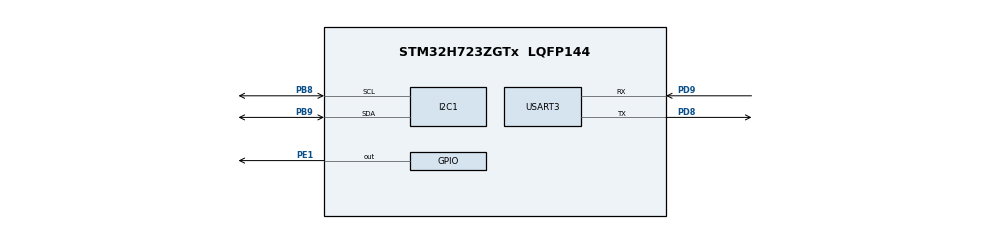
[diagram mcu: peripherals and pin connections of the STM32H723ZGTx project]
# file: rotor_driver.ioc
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CORTEX_M7.AccessPermission-Cortex_Memory_Protection_Unit_Region0_Settings=MPU_REGION_FULL_ACCESS
CORTEX_M7.BaseAddress-Cortex_Memory_Protection_Unit_Region0_Settings=0x30000000
CORTEX_M7.CPU_DCache=Disabled
CORTEX_M7.CPU_ICache=Disabled
CORTEX_M7.DisableExec-Cortex_Memory_Protection_Unit_Region0_Settings=MPU_INSTRUCTION_ACCESS_DISABLE
CORTEX_M7.Enable-Cortex_Memory_Protection_Unit_Region0_Settings=MPU_REGION_ENABLE
CORTEX_M7.Enable-Cortex_Memory_Protection_Unit_Region2_Settings=__NULL
CORTEX_M7.IsShareable-Cortex_Memory_Protection_Unit_Region0_Settings=MPU_ACCESS_SHAREABLE
CORTEX_M7.MPU_Control=__NULL
CORTEX_M7.Size-Cortex_Memory_Protection_Unit_Region0_Settings=MPU_REGION_SIZE_32KB
CORTEX_M7.TypeExtField-Cortex_Memory_Protection_Unit_Region0_Settings=MPU_TEX_LEVEL1
I2C1.Timing=0x00707CBB
Mcu.Family=STM32H7
Mcu.Name=STM32H723ZGTx
Mcu.Package=LQFP144
NVIC.PriorityGroup=NVIC_PRIORITYGROUP_4
NVIC.USART3_IRQn=true\:0\:0\:false\:false\:true\:true\:true
PB8.Mode=I2C
PB8.Signal=I2C1_SCL
PB9.Mode=I2C
PB9.Signal=I2C1_SDA
PD8.Mode=Asynchronous
PD8.Signal=USART3_TX
PD9.Mode=Asynchronous
PD9.Signal=USART3_RX
PE1.PinState=GPIO_PIN_SET
PE1.Signal=GPIO_Output
ProjectManager.HeapSize=0x200
ProjectManager.StackSize=0x400
ProjectManager.TargetToolchain=STM32CubeIDE
RCC.ADCFreq_Value=129000000
RCC.APB1Freq_Value=32000000
RCC.APB2Freq_Value=32000000
RCC.APB3Freq_Value=32000000
RCC.APB4Freq_Value=32000000
RCC.CortexFreq_Value=64000000
RCC.D1PPRE=RCC_APB3_DIV2
RCC.D2PPRE1=RCC_APB1_DIV2
RCC.D2PPRE2=RCC_APB2_DIV2
RCC.D3PPRE=RCC_APB4_DIV2
RCC.HCLKFreq_Value=64000000
RCC.SYSCLKFreq_VALUE=64000000
RCC.USBFreq_Value=129000000
USART3.VirtualMode-Asynchronous=VM_ASYNC
board=custom

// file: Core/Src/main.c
/* USER CODE BEGIN Header */
/**
 ******************************************************************************
 * @file           : main.c
 * @brief          : Main program body
 ******************************************************************************
 * @attention
 *
 * Copyright (c) 2022 STMicroelectronics.
 * All rights reserved.
 *
 * This software is licensed under terms that can be found in the LICENSE file
 * in the root directory of this software component.
 * If no LICENSE file comes with this software, it is provided AS-IS.
 *
 ******************************************************************************
 */
/* USER CODE END Header */
#include "main.h"

#include "gpio.h"
#include "i2c.h"
#include "usart.h"

/* USER CODE BEGIN Includes */

#include "rotor_driver.h"
#include "serial_driver.h"
/* USER CODE END Includes */

void SystemClock_Config(void);

int main(void)
{

    /* MCU Configuration--------------------------------------------------------*/

    /* Reset of all peripherals, Initializes the Flash interface and the
     * Systick. */
    HAL_Init();

    /* Configure the system clock */
    SystemClock_Config();

    /* Initialize all configured peripherals */
    MX_GPIO_Init();
    MX_USART3_UART_Init();
    MX_I2C1_Init();

    /* Infinite loop */
    /* USER CODE BEGIN WHILE */

    ROTOR_Setup(&hi2c1, 300);
    SERIAL_WaitForCommandIndicator();

    while (1)
    {
        /* USER CODE END WHILE */

    }
}

void SystemClock_Config(void)
{
    RCC_OscInitTypeDef RCC_OscInitStruct = {0};
    RCC_ClkInitTypeDef RCC_ClkInitStruct = {0};

    /** Supply configuration update enable
     */
    HAL_PWREx_ConfigSupply(PWR_LDO_SUPPLY);
    /** Configure the main internal regulator output voltage
     */
    __HAL_PWR_VOLTAGESCALING_CONFIG(PWR_REGULATOR_VOLTAGE_SCALE3);

    while (!__HAL_PWR_GET_FLAG(PWR_FLAG_VOSRDY))
    {}
    /** Initializes the RCC Oscillators according to the specified parameters
     * in the RCC_OscInitTypeDef structure.
     */
    RCC_OscInitStruct.OscillatorType = RCC_OSCILLATORTYPE_HSI;
    RCC_OscInitStruct.HSIState = RCC_HSI_DIV1;
    RCC_OscInitStruct.HSICalibrationValue = RCC_HSICALIBRATION_DEFAULT;
    RCC_OscInitStruct.PLL.PLLState = RCC_PLL_NONE;
    if (HAL_RCC_OscConfig(&RCC_OscInitStruct) != HAL_OK)
    {
        Error_Handler();
    }
    /** Initializes the CPU, AHB and APB buses clocks
     */
    RCC_ClkInitStruct.ClockType = RCC_CLOCKTYPE_HCLK | RCC_CLOCKTYPE_SYSCLK |
                                  RCC_CLOCKTYPE_PCLK1 | RCC_CLOCKTYPE_PCLK2 |
                                  RCC_CLOCKTYPE_D3PCLK1 | RCC_CLOCKTYPE_D1PCLK1;
    RCC_ClkInitStruct.SYSCLKSource = RCC_SYSCLKSOURCE_HSI;
    RCC_ClkInitStruct.SYSCLKDivider = RCC_SYSCLK_DIV1;
    RCC_ClkInitStruct.AHBCLKDivider = RCC_HCLK_DIV1;
    RCC_ClkInitStruct.APB3CLKDivider = RCC_APB3_DIV2;
    RCC_ClkInitStruct.APB1CLKDivider = RCC_APB1_DIV2;
    RCC_ClkInitStruct.APB2CLKDivider = RCC_APB2_DIV2;
    RCC_ClkInitStruct.APB4CLKDivider = RCC_APB4_DIV2;

    if (HAL_RCC_ClockConfig(&RCC_ClkInitStruct, FLASH_LATENCY_1) != HAL_OK)
    {
        Error_Handler();
    }
}

void Error_Handler(void)
{
    /* USER CODE BEGIN Error_Handler_Debug */
    /* User can add his own implementation to report the HAL error return state */
    __disable_irq();
    while (1)
    {}
    /* USER CODE END Error_Handler_Debug */
}

#ifdef USE_FULL_ASSERT
/**
 * @brief  Reports the name of the source file and the source line number
 *         where the assert_param error has occurred.
 * @param  file: pointer to the source file name
 * @param  line: assert_param error line source number
 * @retval None
 */
void assert_failed(uint8_t* file, uint32_t line)
{
    /* USER CODE BEGIN 6 */
    /* User can add his own implementation to report the file name and line
       number, ex: printf("Wrong parameters value: file %s on line %d\r\n",
       file, line) */
    /* USER CODE END 6 */
}
#endif /* USE_FULL_ASSERT */
